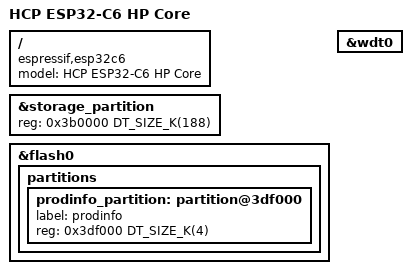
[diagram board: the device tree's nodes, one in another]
/*
 * HCP (Helios Collector Platform) — ESP32-C6 hpcore board.
 * Shared skeleton lives in ../common/hcp_base.dtsi.
 * Copyright (c) 2026 maybetaken
 *
 * SPDX-License-Identifier: Apache-2.0
 */

/dts-v1/;

#include <espressif/esp32c6/esp32c6_wroom_n8.dtsi>
#include <espressif/partitions_0x0_default.dtsi>
#include "hcp_c6_hpcore-pinctrl.dtsi"

#define HCP_SRAM sramhp
#define HCP_BTN_GPIO 9

/ {
	model = "HCP ESP32-C6 HP Core";
	compatible = "espressif,esp32c6";
};

#include "../common/hcp_base.dtsi"
#include "../common/hcp_ws2812.dtsi"

/*
 * Factory identity blob (hcp::identity reads "prodinfo" before falling back to
 * storage / the station MAC), carved out of the tail of the "storage" partition:
 * settings+NVS only ever uses the first 32 KB (CONFIG_SETTINGS_NVS_SECTOR_COUNT=8)
 * of its 192 KB, and the partition keeps its 0x3b0000 start, so credentials
 * already written in the field stay valid. Burning a per-device sn.bin at
 * 0x3df000 with esptool therefore needs no rebuild of the application image.
 */
&storage_partition {
	reg = <0x3b0000 DT_SIZE_K(188)>;
};

&flash0 {
	partitions {
		prodinfo_partition: partition@3df000 {
			label = "prodinfo";
			reg = <0x3df000 DT_SIZE_K(4)>;
		};
	};
};

/*
 * MWDT0 (alias watchdog0): hcp::ota arms a reset deadline on it while this boot
 * is an unconfirmed trial image, so a firmware that never gets healthy rolls
 * itself back. Enabled only here and on hcp_c3 - the boards that boot through
 * MCUboot, where a reset is recoverable.
 */
&wdt0 {
	status = "okay";
};
